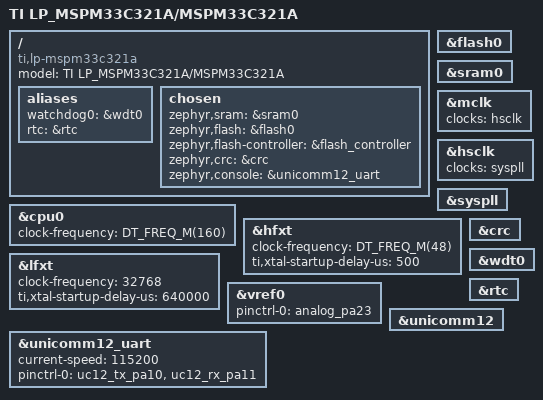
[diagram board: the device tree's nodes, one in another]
/*
 * Copyright (c) 2026 Texas Instruments
 * SPDX-License-Identifier: Apache-2.0
 */

/dts-v1/;

#include <ti/mspm33c/mspm33c321a.dtsi>
#include <ti/mspm33c/mspm33c321a-pinctrl.dtsi>
#include <zephyr/dt-bindings/pinctrl/mspm0-pinctrl.h>

/ {
	compatible = "ti,lp-mspm33c321a";
	model = "TI LP_MSPM33C321A/MSPM33C321A";

	aliases {
		watchdog0 = &wdt0;
		rtc = &rtc;
	};

	chosen {
		zephyr,sram = &sram0;
		zephyr,flash = &flash0;
		zephyr,flash-controller = &flash_controller;
		zephyr,crc = &crc;
		zephyr,console = &unicomm12_uart;
	};
};

&flash0 {
	status = "okay";
};

&sram0 {
	status = "okay";
};

&cpu0 {
	clock-frequency = <DT_FREQ_M(160)>;
};

&mclk {
	clocks = <&hsclk>;
};

&hsclk {
	clocks = <&syspll>;
	status = "okay";
};

&syspll {
	status = "okay";
};

&hfxt {
	clock-frequency = <DT_FREQ_M(48)>;
	ti,xtal-startup-delay-us = <500>;
};

&lfxt {
	clock-frequency = <32768>;
	ti,xtal-startup-delay-us = <640000>;
};

&crc {
	status = "okay";
};

&vref0 {
	pinctrl-0 = <&analog_pa23>;
	pinctrl-names = "default";
	status = "okay";
};

&wdt0 {
	status = "okay";
};

&rtc {
	status = "okay";
};

&unicomm12 {
	status = "okay";
};

&unicomm12_uart {
	current-speed = <115200>;
	pinctrl-0 = <&uc12_tx_pa10 &uc12_rx_pa11>;
	pinctrl-names = "default";
	status = "okay";
};
